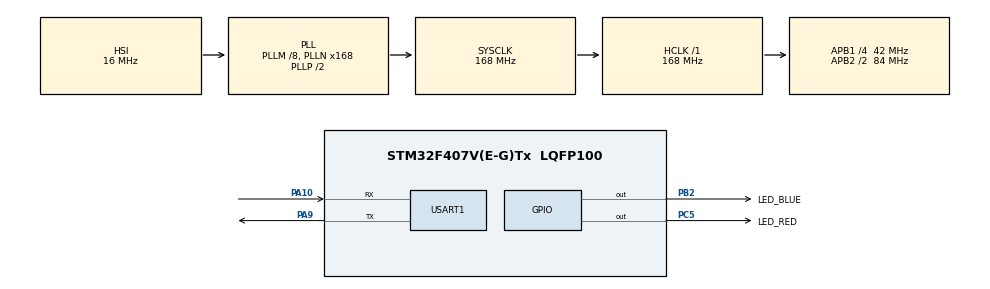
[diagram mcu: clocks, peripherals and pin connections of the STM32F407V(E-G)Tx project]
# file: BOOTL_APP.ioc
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FREERTOS.Tasks01=defaultTask,24,1024,StartDefaultTask,Default,NULL,Dynamic,NULL,NULL
FREERTOS.configUSE_IDLE_HOOK=1
Mcu.Family=STM32F4
Mcu.Name=STM32F407V(E-G)Tx
Mcu.Package=LQFP100
NVIC.PriorityGroup=NVIC_PRIORITYGROUP_4
NVIC.TIM7_IRQn=true\:15\:0\:false\:false\:true\:false\:false\:true\:true
NVIC.TimeBase=TIM7_IRQn
NVIC.TimeBaseIP=TIM7
NVIC.USART1_IRQn=true\:10\:0\:true\:false\:true\:true\:true\:true\:true
PA10.Mode=Asynchronous
PA10.Signal=USART1_RX
PA13.Mode=Serial_Wire
PA13.Signal=SYS_JTMS-SWDIO
PA14.Mode=Serial_Wire
PA14.Signal=SYS_JTCK-SWCLK
PA9.Mode=Asynchronous
PA9.Signal=USART1_TX
PB2.GPIO_Label=LED_BLUE
PB2.GPIO_ModeDefaultOutputPP=GPIO_MODE_OUTPUT_PP
PB2.GPIO_PuPd=GPIO_PULLUP
PB2.GPIO_Speed=GPIO_SPEED_FREQ_HIGH
PB2.PinState=GPIO_PIN_SET
PB2.Signal=GPIO_Output
PC5.GPIO_Label=LED_RED
PC5.GPIO_PuPd=GPIO_PULLUP
PC5.GPIO_Speed=GPIO_SPEED_FREQ_HIGH
PC5.PinState=GPIO_PIN_SET
PC5.Signal=GPIO_Output
PH0-OSC_IN.Mode=HSE-External-Oscillator
PH0-OSC_IN.Signal=RCC_OSC_IN
PH1-OSC_OUT.Mode=HSE-External-Oscillator
PH1-OSC_OUT.Signal=RCC_OSC_OUT
ProjectManager.HeapSize=0x200
ProjectManager.StackSize=0x400
ProjectManager.TargetToolchain=CMake
RCC.48MHZClocksFreq_Value=84000000
RCC.AHBFreq_Value=168000000
RCC.APB1CLKDivider=RCC_HCLK_DIV4
RCC.APB1Freq_Value=42000000
RCC.APB1TimFreq_Value=84000000
RCC.APB2CLKDivider=RCC_HCLK_DIV2
RCC.APB2Freq_Value=84000000
RCC.APB2TimFreq_Value=168000000
RCC.CortexFreq_Value=168000000
RCC.HCLKFreq_Value=168000000
RCC.HSE_VALUE=25000000
RCC.HSI_VALUE=16000000
RCC.LSE_VALUE=32768
RCC.PLLM=8
RCC.PLLN=168
RCC.SYSCLKFreq_VALUE=168000000
RCC.SYSCLKSource=RCC_SYSCLKSOURCE_PLLCLK
RCC.VCOOutputFreq_Value=336000000
USART1.VirtualMode=VM_ASYNC
VP_FREERTOS_VS_CMSIS_V2.Mode=CMSIS_V2
VP_SYS_VS_tim7.Mode=TIM7
board=custom

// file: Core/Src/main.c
/* USER CODE BEGIN Header */
/**
  ******************************************************************************
  * @file           : main.c
  * @brief          : Main program body
  ******************************************************************************
  * @attention
  *
  * Copyright (c) 2025 STMicroelectronics.
  * All rights reserved.
  *
  * This software is licensed under terms that can be found in the LICENSE file
  * in the root directory of this software component.
  * If no LICENSE file comes with this software, it is provided AS-IS.
  *
  ******************************************************************************
  */
/* USER CODE END Header */
#include "main.h"
#include "cmsis_os.h"
#include "usart.h"
#include "gpio.h"

void SystemClock_Config(void);
void MX_FREERTOS_Init(void);

int main(void)
{

  /* MCU Configuration--------------------------------------------------------*/

  /* Reset of all peripherals, Initializes the Flash interface and the Systick. */
  HAL_Init();

  /* Configure the system clock */
  SystemClock_Config();

  /* Initialize all configured peripherals */
  MX_GPIO_Init();
  MX_USART1_UART_Init();

  /* Init scheduler */
  osKernelInitialize();  /* Call init function for freertos objects (in cmsis_os2.c) */
  MX_FREERTOS_Init();

  /* Start scheduler */
  osKernelStart();

  /* We should never get here as control is now taken by the scheduler */

  /* Infinite loop */
  while (1)
  {

  }
}

void SystemClock_Config(void)
{
  RCC_OscInitTypeDef RCC_OscInitStruct = {0};
  RCC_ClkInitTypeDef RCC_ClkInitStruct = {0};

  /** Configure the main internal regulator output voltage
  */
  __HAL_RCC_PWR_CLK_ENABLE();
  __HAL_PWR_VOLTAGESCALING_CONFIG(PWR_REGULATOR_VOLTAGE_SCALE1);

  /** Initializes the RCC Oscillators according to the specified parameters
  * in the RCC_OscInitTypeDef structure.
  */
  RCC_OscInitStruct.OscillatorType = RCC_OSCILLATORTYPE_HSI;
  RCC_OscInitStruct.HSIState = RCC_HSI_ON;
  RCC_OscInitStruct.HSICalibrationValue = RCC_HSICALIBRATION_DEFAULT;
  RCC_OscInitStruct.PLL.PLLState = RCC_PLL_ON;
  RCC_OscInitStruct.PLL.PLLSource = RCC_PLLSOURCE_HSI;
  RCC_OscInitStruct.PLL.PLLM = 8;
  RCC_OscInitStruct.PLL.PLLN = 168;
  RCC_OscInitStruct.PLL.PLLP = RCC_PLLP_DIV2;
  RCC_OscInitStruct.PLL.PLLQ = 4;
  if (HAL_RCC_OscConfig(&RCC_OscInitStruct) != HAL_OK)
  {
    Error_Handler();
  }

  /** Initializes the CPU, AHB and APB buses clocks
  */
  RCC_ClkInitStruct.ClockType = RCC_CLOCKTYPE_HCLK|RCC_CLOCKTYPE_SYSCLK
                              |RCC_CLOCKTYPE_PCLK1|RCC_CLOCKTYPE_PCLK2;
  RCC_ClkInitStruct.SYSCLKSource = RCC_SYSCLKSOURCE_PLLCLK;
  RCC_ClkInitStruct.AHBCLKDivider = RCC_SYSCLK_DIV1;
  RCC_ClkInitStruct.APB1CLKDivider = RCC_HCLK_DIV4;
  RCC_ClkInitStruct.APB2CLKDivider = RCC_HCLK_DIV2;

  if (HAL_RCC_ClockConfig(&RCC_ClkInitStruct, FLASH_LATENCY_5) != HAL_OK)
  {
    Error_Handler();
  }
}

void HAL_TIM_PeriodElapsedCallback(TIM_HandleTypeDef *htim)
{
  if (htim->Instance == TIM7)
  {
    HAL_IncTick();
  }
}

void Error_Handler(void)
{
  __disable_irq();
  while (1)
  {
  }
}

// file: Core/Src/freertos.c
/* USER CODE BEGIN Header */
/**
  ******************************************************************************
  * File Name          : freertos.c
  * Description        : Code for freertos applications
  ******************************************************************************
  * @attention
  *
  * Copyright (c) 2025 STMicroelectronics.
  * All rights reserved.
  *
  * This software is licensed under terms that can be found in the LICENSE file
  * in the root directory of this software component.
  * If no LICENSE file comes with this software, it is provided AS-IS.
  *
  ******************************************************************************
  */
/* USER CODE END Header */

#include "FreeRTOS.h"
#include "task.h"
#include "main.h"
#include "cmsis_os.h"

/* USER CODE BEGIN Includes */
#include "update_manager.h"
#include "gpio.h"
#include "comm_proto.h"
/* USER CODE END Includes */

/* Definitions for defaultTask */
osThreadId_t defaultTaskHandle;
const osThreadAttr_t defaultTask_attributes = {
  .name = "defaultTask",
  .stack_size = 1024 * 4,
  .priority = (osPriority_t) osPriorityNormal,
};

void StartDefaultTask(void *argument);

void MX_FREERTOS_Init(void); /* (MISRA C 2004 rule 8.1) */

/* Hook prototypes */
void vApplicationIdleHook(void);

/* USER CODE BEGIN 2 */
void vApplicationIdleHook( void )
{
   /* vApplicationIdleHook() will only be called if configUSE_IDLE_HOOK is set
   to 1 in FreeRTOSConfig.h. It will be called on each iteration of the idle
   task. It is essential that code added to this hook function never attempts
   to block in any way (for example, call xQueueReceive() with a block time
   specified, or call vTaskDelay()). If the application makes use of the
   vTaskDelete() API function (as this demo application does) then it is also
   important that vApplicationIdleHook() is permitted to return to its calling
   function, because it is the responsibility of the idle task to clean up
   memory allocated by the kernel to any task that has since been deleted. */
  Update_ProcessInIdle();

}
/* USER CODE END 2 */

void MX_FREERTOS_Init(void) {

  /* Create the thread(s) */
  /* creation of defaultTask */
  defaultTaskHandle = osThreadNew(StartDefaultTask, NULL, &defaultTask_attributes);

}

void StartDefaultTask(void *argument)
{
  /* USER CODE BEGIN StartDefaultTask */
  // 初始化升级管理器
  Update_Init();
  // 初始化串口通讯
  Comm_Init();

  /* Infinite loop */
  for(;;)
  {
    // LED闪烁
    HAL_GPIO_TogglePin(LED_BLUE_GPIO_Port,LED_BLUE_Pin);
    HAL_GPIO_TogglePin(LED_RED_GPIO_Port,LED_RED_Pin);
    osDelay(200);
  }
  /* USER CODE END StartDefaultTask */
}
